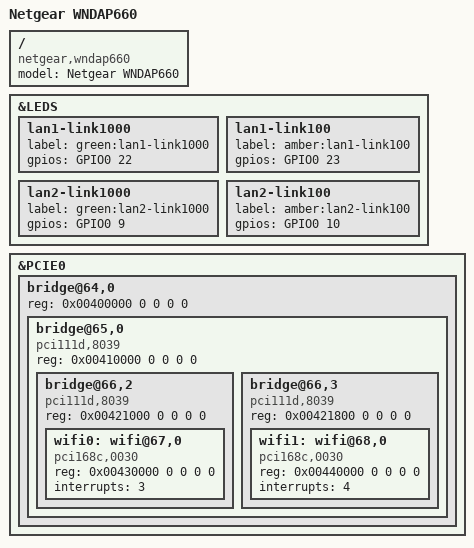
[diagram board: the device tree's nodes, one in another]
// SPDX-License-Identifier: GPL-2.0-only

/dts-v1/;

#include "netgear-wndap6x0.dtsi"

/ {
	model = "Netgear WNDAP660";
	compatible = "netgear,wndap660", "apm,bluestone";
};

&LEDS {
	lan1-link1000 {
		label = "green:lan1-link1000";
		gpios = <&GPIO0 22 GPIO_ACTIVE_HIGH>;
	};

	lan1-link100 {
		label = "amber:lan1-link100";
		gpios = <&GPIO0 23 GPIO_ACTIVE_HIGH>;
	};

	lan2-link1000 {
		label = "green:lan2-link1000";
		gpios = <&GPIO0 9 GPIO_ACTIVE_HIGH>;
	};

	lan2-link100 {
		label = "amber:lan2-link100";
		gpios = <&GPIO0 10 GPIO_ACTIVE_HIGH>;
	};
};

&PCIE0 {
	/*
	 * relevant lspci topology:
	 *
	 *	-+-[0000:40]---00.0-[41-7f]----00.0-[42-45]--+-02.0-[43]----00.0
	 *	                                             +-03.0-[44]----00.0
	 *
	 */

	bridge@64,0 {
		reg = <0x00400000 0 0 0 0>;
		#address-cells = <3>;
		#size-cells = <2>;
		ranges;

		bridge@65,0 {
			/* IDT PES3T3 PCI Express Switch */
			compatible = "pci111d,8039";
			reg = <0x00410000 0 0 0 0>;
			#address-cells = <3>;
			#size-cells = <2>;
			ranges;

			bridge@66,2 {
				compatible = "pci111d,8039";
				reg = <0x00421000 0 0 0 0>;
				#address-cells = <3>;
				#size-cells = <2>;
				ranges;

				wifi0: wifi@67,0 {
					/* Atheros AR9380 2.4/5GHz */
					compatible = "pci168c,0030";
					reg = <0x00430000 0 0 0 0>;
					interrupts = <3>; /* INTC */
				};
			};

			bridge@66,3 {
				compatible = "pci111d,8039";
				reg = <0x00421800 0 0 0 0>;
				#address-cells = <3>;
				#size-cells = <2>;
				ranges;

		                wifi1: wifi@68,0 {
					/* Atheros AR9380 2.4/5GHz */
					compatible = "pci168c,0030";
					reg = <0x00440000 0 0 0 0>;
					interrupts = <4>; /* INTD */
				};
			};
		};
	};
};
